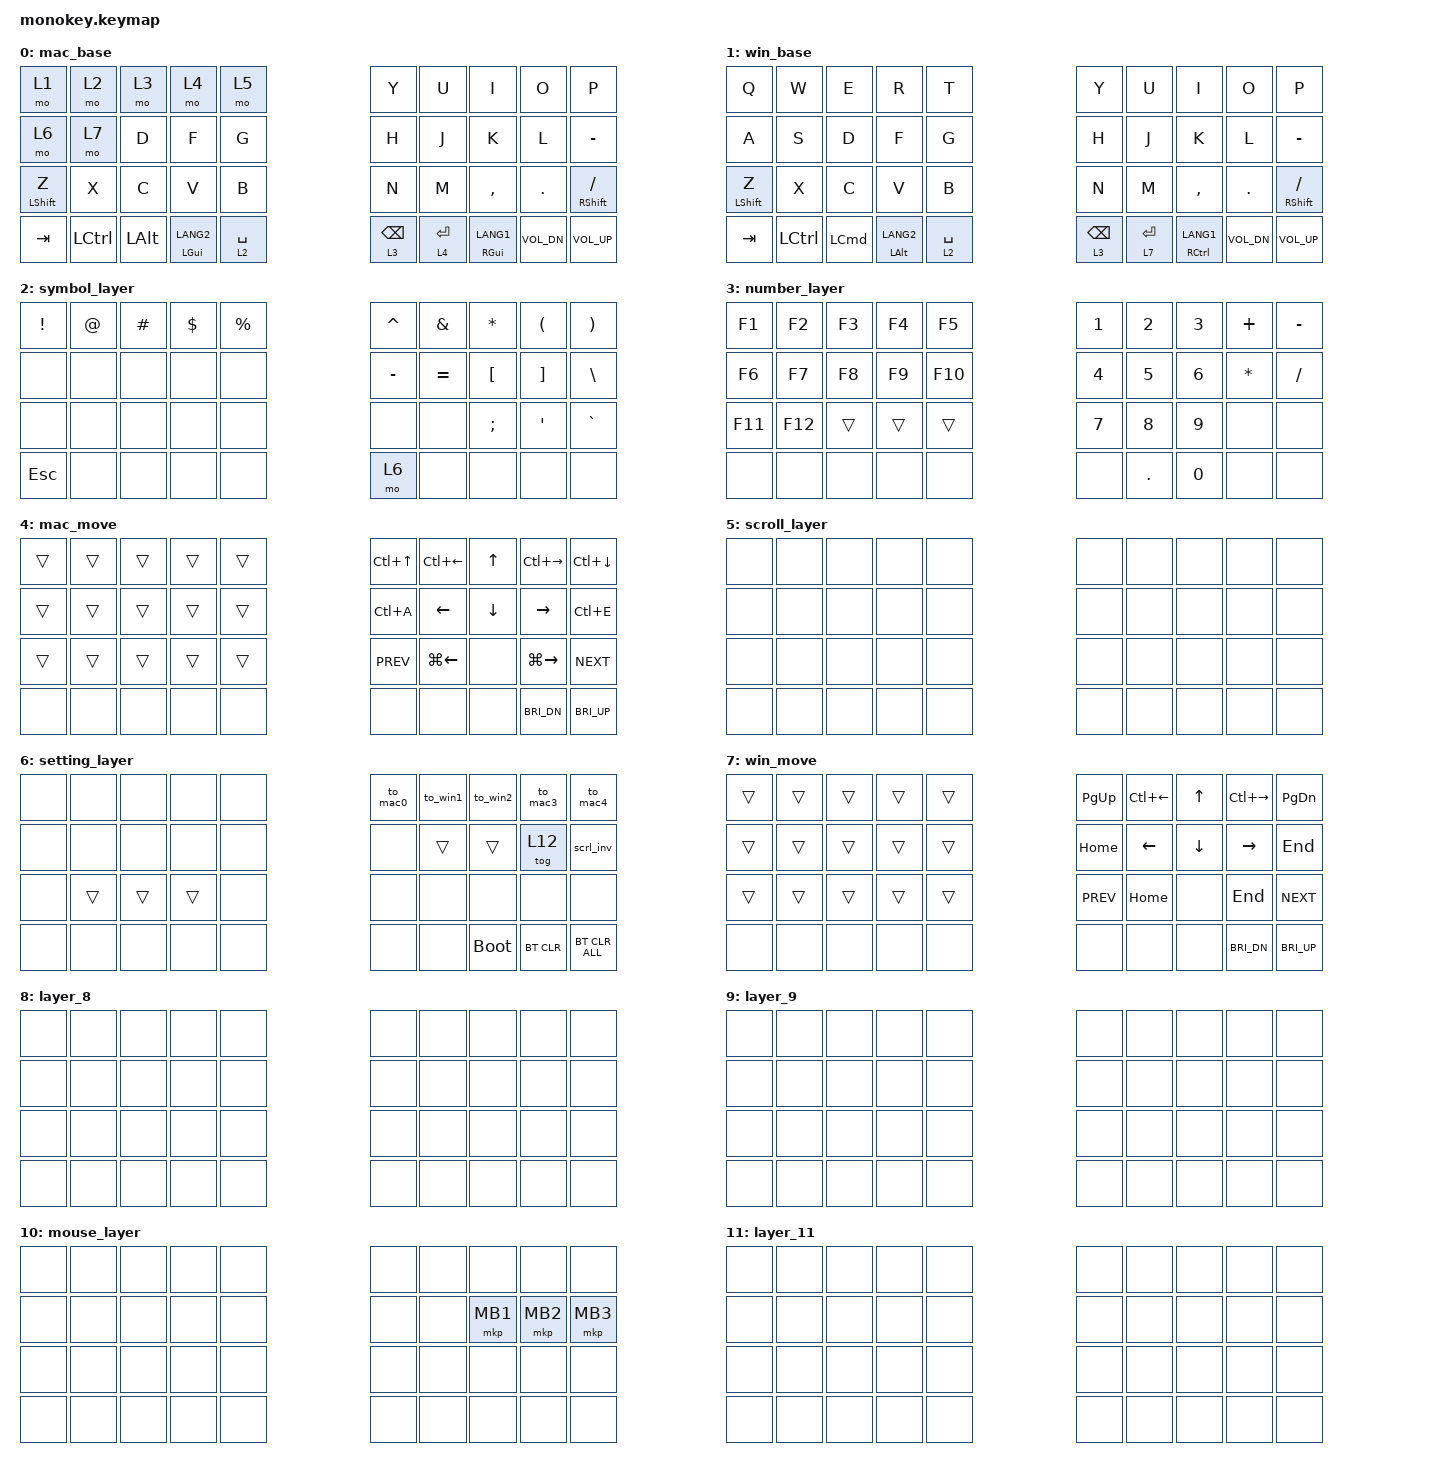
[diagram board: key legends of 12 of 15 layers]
/*
 * Copyright (c) 2024 Conductor Keyboard
 * Generated by Conductor Studio 2.0
 */

#include <dt-bindings/zmk/mouse.h>
#include <behaviors.dtsi>
#include <dt-bindings/zmk/bt.h>
#include <dt-bindings/zmk/keys.h>
#include <dt-bindings/zmk/pointing.h>

&mt {
    flavor = "tap-preferred";
    tapping-term-ms = <150>;
    quick-tap-ms = <250>;
};

&lt {
    tapping-term-ms = <150>;
    quick-tap-ms = <300>;
    flavor = "tap-preferred";
    retro-tap;
};

/ {
    behaviors {
        /* Shift-only relaxed mod-tap: eager hold + retro-tap to fix
         * "Shift sometimes does not register". Scoped to Shift (bare tap has
         * no side effect) so the GUI/LANG mod-taps keep the stock &mt and do
         * not emit a bare GUI press (Start menu on Win/Linux). */

        mt_shift: mt_shift {
            compatible = "zmk,behavior-hold-tap";
            #binding-cells = <2>;
            flavor = "tap-preferred";
            tapping-term-ms = <150>;
            quick-tap-ms = <250>;
            hold-while-undecided;
            retro-tap;
            bindings = <&kp>, <&kp>;
        };

        /* 接続切替マクロ用: レイヤーを ON 固定 / OFF 固定するトグル behavior。
         * conductor フォーク(pite1222/zmk@release/conductor-0.5.4)で
         * behavior-toggle-layer の toggle-mode=on/off 対応を確認済み。 */

        tog_on: tog_on {
            compatible = "zmk,behavior-toggle-layer";
            #binding-cells = <1>;
            display-name = "Toggle Layer On";
            toggle-mode = "on";
        };

        tog_off: tog_off {
            compatible = "zmk,behavior-toggle-layer";
            #binding-cells = <1>;
            display-name = "Toggle Layer Off";
            toggle-mode = "off";
        };
    };

    /* 接続先プロファイル切替 ＋ OSベース自動切替マクロ。
     * BT_SEL 1・2 = Win（win_base=1 を ON）/ それ以外(0・3・4) = Mac（win_base を OFF）。
     * Mac系も tog_off を含めるのは Win→Mac で win_base を確実に外すため。
     * 切替キーは単独で押すこと（実行中 約0.2〜0.7秒は他キーと競合しうる）。
     * setting レイヤー(idx6)の BT_SEL 位置に割当てる。 */

    macros {
        to_mac0: to_mac0 {
            compatible = "zmk,behavior-macro";
            #binding-cells = <0>;
            wait-ms = <30>;
            tap-ms = <30>;
            bindings = <&tog_off 1>, <&macro_wait_time 200>, <&bt BT_SEL 0>;
        };

        to_win1: to_win1 {
            compatible = "zmk,behavior-macro";
            #binding-cells = <0>;
            wait-ms = <30>;
            tap-ms = <30>;
            bindings =
                <&tog_off 1>,
                <&macro_wait_time 200>,
                <&bt BT_SEL 1>,
                <&macro_wait_time 500>,
                <&tog_on 1>;
        };

        to_win2: to_win2 {
            compatible = "zmk,behavior-macro";
            #binding-cells = <0>;
            wait-ms = <30>;
            tap-ms = <30>;
            bindings =
                <&tog_off 1>,
                <&macro_wait_time 200>,
                <&bt BT_SEL 2>,
                <&macro_wait_time 500>,
                <&tog_on 1>;
        };

        to_mac3: to_mac3 {
            compatible = "zmk,behavior-macro";
            #binding-cells = <0>;
            wait-ms = <30>;
            tap-ms = <30>;
            bindings = <&tog_off 1>, <&macro_wait_time 200>, <&bt BT_SEL 3>;
        };

        to_mac4: to_mac4 {
            compatible = "zmk,behavior-macro";
            #binding-cells = <0>;
            wait-ms = <30>;
            tap-ms = <30>;
            bindings = <&tog_off 1>, <&macro_wait_time 200>, <&bt BT_SEL 4>;
        };
    };

    combos {
        compatible = "zmk,combos";

        scroll {
            bindings = <&mo 5>;
            key-positions = <17 18>;
            timeout-ms = <50>;
        };

        /* Mac: I+O でジェスチャーレイヤー(13)へ。mac_base(0) のときだけ発火。
         * ジェスチャーは OS で挙動が違い共有できないため Mac/Win を別レイヤーに分離。 */
        gesture {
            bindings = <&mo 13>;
            key-positions = <7 8>;
            layers = <0>;
            timeout-ms = <50>;
        };

        /* Win: I+O で Win 用ジェスチャーレイヤー(14)へ。win_base(1) のときだけ発火。
         * Mac の gesture と同じ I+O だが、最上位アクティブ層が 0/1 で自動振り分け。 */
        win_gesture {
            bindings = <&mo 14>;
            key-positions = <7 8>;
            layers = <1>;
            timeout-ms = <50>;
        };

        pair {
            bindings = <&bt BT_SEL 5>;
            key-positions = <0 10 20>;
            timeout-ms = <50>;
        };

        boot {
            bindings = <&bootloader>;
            key-positions = <8 24 4>;
            timeout-ms = <50>;
        };
    };

    keymap {
        compatible = "zmk,keymap";

        /* idx 0: Mac ベース（起動時の既定レイヤー）。
         * 現行 default から &lt 番号のみ更新（symbol 1→2 / number 2→3 / move 3→4）。 */

        mac_base {
            bindings = <
&mo 1               &mo 2      &mo 3     &mo 4           &mo 5                                 &kp Y           &kp U  &kp I      &kp O         &kp P
&mo 6               &mo 7      &kp D     &kp F           &kp G                                 &kp H           &kp J  &kp K      &kp L         &kp MINUS
&mt_shift LSHIFT Z  &kp X      &kp C     &kp V           &kp B                                 &kp N           &kp M  &kp COMMA  &kp DOT       &mt_shift RSHIFT FSLH
&kp TAB             &kp LCTRL  &kp LALT  &mt LGUI LANG2  &lt 2 SPACE  &lt 3 BSPC  &lt 4 ENTER  &mt RGUI LANG1                    &kp C_VOL_DN  &kp C_VOL_UP
            >;

            sensor-bindings = <&inc_dec_kp PG_UP PG_DN>;
        };

        /* idx 1: Windows ベース（to_win1/to_win2 マクロでトグル ON）。
         * mac_base の差分版。&trans を一切持たない「フル定義」なので、
         * トグル ON で mac_base を完全に覆う（透けて Cmd が出るのを防ぐ）。
         * mac_base との差分は4箇所:
         *   親指内左  &mt LGUI→LCTRL  / 親指内右 &mt RGUI→RCTRL（コピー等を Win=Ctrl に）
         *   ENTER     &lt 4→7（mac_move→win_move）
         *   左下       &kp LCTRL→LGUI（内親指が Ctrl化したので Win キーを確保）
         * 🟡 IME: Win は LANG1/LANG2 が既定で IME に渡らない環境が多い。
         *    効かなければ INT5(無変換)/INT4(変換) or GRAVE(半角/全角) を実機で要調整。 */

        win_base {
            bindings = <
&kp Q               &kp W      &kp E     &kp R               &kp T                                 &kp Y            &kp U  &kp I      &kp O         &kp P
&kp A               &kp S      &kp D     &kp F               &kp G                                 &kp H            &kp J  &kp K      &kp L         &kp MINUS
&mt_shift LSHIFT Z  &kp X      &kp C     &kp V               &kp B                                 &kp N            &kp M  &kp COMMA  &kp DOT       &mt_shift RSHIFT FSLH
&kp TAB             &kp LCTRL  &kp LCMD  &mt LEFT_ALT LANG2  &lt 2 SPACE  &lt 3 BSPC  &lt 7 ENTER  &mt RCTRL LANG1                    &kp C_VOL_DN  &kp C_VOL_UP
            >;

            sensor-bindings = <&inc_dec_kp PG_UP PG_DN>;
        };

        symbol_layer {
            bindings = <
&kp EXCL  &kp AT  &kp HASH  &kp DLLR  &kp PRCNT                &kp CARET  &kp AMPS   &kp STAR  &kp LPAR  &kp RPAR
&none     &none   &none     &none     &none                    &kp MINUS  &kp EQUAL  &kp LBKT  &kp RBKT  &kp BSLH
&none     &none   &none     &none     &none                    &none      &none      &kp SEMI  &kp SQT   &kp GRAVE
&kp ESC   &none   &none     &none     &none      &mo 6  &none  &none                           &none     &none
            >;
        };

        number_layer {
            bindings = <
&kp F1   &kp F2   &kp F3  &kp F4  &kp F5                   &kp N1  &kp N2  &kp N3  &kp PLUS  &kp MINUS
&kp F6   &kp F7   &kp F8  &kp F9  &kp F10                  &kp N4  &kp N5  &kp N6  &kp STAR  &kp FSLH
&kp F11  &kp F12  &trans  &trans  &trans                   &kp N7  &kp N8  &kp N9  &none     &none
&none    &none    &none   &none   &none    &none  &kp DOT  &kp N0                  &none     &none
            >;
        };

        /* idx 4: Mac 版 move（readline LC(A)/LC(E)・Cmd 行移動など現行どおり）。
         * mac_base の &lt 4 ENTER で開く。 */

        mac_move {
            bindings = <
&trans  &trans  &trans  &trans  &trans                &kp LC(UP)  &kp LC(LEFT)  &kp UP    &kp LC(RIGHT)  &kp LC(DOWN)
&trans  &trans  &trans  &trans  &trans                &kp LC(A)   &kp LEFT      &kp DOWN  &kp RIGHT      &kp LC(E)
&trans  &trans  &trans  &trans  &trans                &kp C_PREV  &kp LG(LEFT)  &none     &kp LG(RIGHT)  &kp C_NEXT
&none   &none   &none   &none   &none   &none  &none  &none                               &kp C_BRI_DN   &kp C_BRI_UP
            >;
        };

        scroll_layer {
            bindings = <
&none  &none  &none  &none  &none                &none  &none  &none  &none  &none
&none  &none  &none  &none  &none                &none  &none  &none  &none  &none
&none  &none  &none  &none  &none                &none  &none  &none  &none  &none
&none  &none  &none  &none  &none  &none  &none  &none                &none  &none
            >;
        };

        setting_layer {
            bindings = <
&none  &none   &none   &none   &none                &to_mac0     &to_win1  &to_win2  &to_mac3    &to_mac4
&none  &none   &none   &none   &none                &none        &trans    &trans    &tog 12     &scrl_inv
&none  &trans  &trans  &trans  &none                &none        &none     &none     &none       &none
&none  &none   &none   &none   &none  &none  &none  &bootloader                      &bt BT_CLR  &bt BT_CLR_ALL
            >;
        };

        /* idx 7: Windows 版 move（Home/End/PgUp 等の Win イディオム。実機で要調整）。
         * win_base の &lt 7 ENTER で開く。mac_move と同枠の OS 別差し替え。 */

        win_move {
            bindings = <
&trans  &trans  &trans  &trans  &trans                &kp PG_UP   &kp LC(LEFT)  &kp UP    &kp LC(RIGHT)  &kp PG_DN
&trans  &trans  &trans  &trans  &trans                &kp HOME    &kp LEFT      &kp DOWN  &kp RIGHT      &kp END
&trans  &trans  &trans  &trans  &trans                &kp C_PREV  &kp HOME      &none     &kp END        &kp C_NEXT
&none   &none   &none   &none   &none   &none  &none  &none                               &kp C_BRI_DN   &kp C_BRI_UP
            >;
        };

        layer_8 {
            bindings = <
&none  &none  &none  &none  &none                &none  &none  &none  &none  &none
&none  &none  &none  &none  &none                &none  &none  &none  &none  &none
&none  &none  &none  &none  &none                &none  &none  &none  &none  &none
&none  &none  &none  &none  &none  &none  &none  &none                &none  &none
            >;
        };

        layer_9 {
            bindings = <
&none  &none  &none  &none  &none                &none  &none  &none  &none  &none
&none  &none  &none  &none  &none                &none  &none  &none  &none  &none
&none  &none  &none  &none  &none                &none  &none  &none  &none  &none
&none  &none  &none  &none  &none  &none  &none  &none                &none  &none
            >;
        };

        /* idx 10: AML(automouse)。overlay の &zip_temp_layer 10 の飛び先。
         * 旧 idx4 から移動。全コンテンツ層より上に置くことで、どのレイヤーに
         * いても MB1-3 を押せる（上位レイヤーが MB 位置を覆う継承問題の解消）。
         * MB 以外は &none（＝下位レイヤーは透けない・mouse 専用層）。 */

        mouse_layer {
            bindings = <
&none  &none  &none  &none  &none                &none  &none  &none     &none     &none
&none  &none  &none  &none  &none                &none  &none  &mkp MB1  &mkp MB2  &mkp MB3
&none  &none  &none  &none  &none                &none  &none  &none     &none     &none
&none  &none  &none  &none  &none  &none  &none  &none                   &none     &none
            >;
        };

        layer_11 {
            bindings = <
&none  &none  &none  &none  &none                &none  &none  &none  &none  &none
&none  &none  &none  &none  &none                &none  &none  &none  &none  &none
&none  &none  &none  &none  &none                &none  &none  &none  &none  &none
&none  &none  &none  &none  &none  &none  &none  &none                &none  &none
            >;
        };

        /* PRECISION layer (id=12): when active, trackball movement is scaled
         * down for fine cursor control (drafting, detailed work). Toggle with
         * &tog 12. Default bindings mirror mouse_layer so MB1-3 are reachable
         * during precision use; other keys are intentionally NONE to prevent
         * accidental typing while focused on cursor work. */

        precision_layer {
            bindings = <
&none  &none  &none  &none  &none                &none  &none  &none     &none     &none
&none  &none  &none  &none  &none                &none  &none  &mkp MB1  &mkp MB2  &mkp MB3
&none  &none  &none  &none  &none                &none  &none  &none     &none     &none
&none  &none  &none  &none  &none  &none  &none  &none                   &none     &tog 12
            >;
        };

        /* GESTURE layer (id=13・Mac用): フリック 上/左/右/下 → LC(↑/←/→/↓)。
         * mac_base から combo I+O(layers=<0>) で入る。overlay の
         * trackball_gestures(layer-id=13) がこの層の binding を発火させる。 */

        gesture_layer {
            bindings = <
&none  &none  &none  &none  &none                &none  &none         &kp LC(UP)    &none          &none
&none  &none  &none  &none  &none                &none  &kp LC(LEFT)  &none         &kp LC(RIGHT)  &none
&none  &none  &none  &none  &none                &none  &none         &kp LC(DOWN)  &none          &none
&none  &none  &none  &none  &none  &none  &none  &none                              &none          &none
            >;
        };

        /* WIN_GESTURE layer (id=14・Windows用): gesture_layer の Win 版。
         * win_base から combo I+O(layers=<1>) で入る。overlay の
         * trackball_gestures_win(layer-id=14) がこの層の binding を発火させる。
         *   フリック上 (I/7)    → LG(TAB)        : タスクビュー（開いているアプリ一覧）
         *   フリック左 (J/16)   → LG(LC(LEFT))   : 左の仮想デスクトップへ
         *   フリック右 (L/18)   → LG(LC(RIGHT))  : 右の仮想デスクトップへ
         *   フリック下 (,/27)   → &none          : Win に好適なショートカットなし
         * ※ 仮想デスクトップ切替は Win+Ctrl+矢印（Ctrl 単独では単語移動になる）。 */

        win_gesture_layer {
            bindings = <
&none  &none  &none  &none  &none                &none  &none              &kp LG(TAB)  &none              &none
&none  &none  &none  &none  &none                &none  &kp LG(LC(LEFT))   &none        &kp LG(LC(RIGHT))  &none
&none  &none  &none  &none  &none                &none  &none              &none        &none              &none
&none  &none  &none  &none  &none  &none  &none  &none                                  &none              &none
            >;
        };
    };
};
